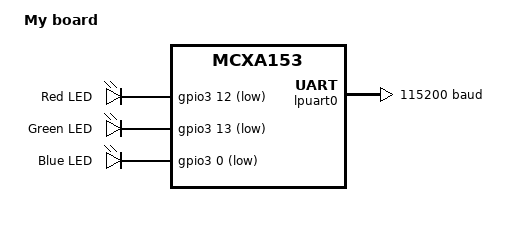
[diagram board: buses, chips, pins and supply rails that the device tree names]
/dts-v1/;

#include <nxp/nxp_mcxa153.dtsi>
#include "hello_world_scratch_method.dtsi"


/ {
	model = "My board";
	compatible = "iomico,my_board";

	aliases{
		led0 = &red_led;
		led1 = &green_led;
		led2 = &blue_led;
	};

	chosen{
		zephyr,sram = &sram0;
		zephyr,flash = &flash;
		zephyr,flash-controller = &fmu;
		zephyr,code-partition = &slot0_partition;
		zephyr,console = &lpuart0;
		zephyr,shell-uart = &lpuart0;
	};

	leds{
		compatible = "gpio-leds";

		red_led: led_0 {
			gpios = <&gpio3 12 GPIO_ACTIVE_LOW>;
			label = "Red LED";
		};

		green_led: led_1 {
			gpios = <&gpio3 13 GPIO_ACTIVE_LOW>;
			label = "Green LED";
		};

		blue_led: led_2 {
			gpios = <&gpio3 0 GPIO_ACTIVE_LOW>;
			label = "Blue LED";
		};
	};
};

&gpio3 {
	status = "okay";
};

&flash {
	partitions {
		compatible = "fixed-partitions";
		#address-cells = <1>;
		#size-cells = <1>;

		boot_partition: partition@0 {
			label = "mcuboot";
			reg = <0x00000000 DT_SIZE_K(32)>;
			read-only;
		};
		slot0_partition: partition@8000 {
			label = "image-0";
			reg = <0x00008000 DT_SIZE_K(40)>;
		};
		slot1_partition: partition@12000 {
			label = "image-1";
			reg = <0x00012000 DT_SIZE_K(40)>;
		};
		storage_partition: partition@1C000 {
			label = "storage";
			reg = <0x0001C000 DT_SIZE_K(16)>;
		};
	};
};

&lpuart0 {
	status = "okay";
	current-speed = <115200>;
	pinctrl-0 = <&pinmux_lpuart0>;
	pinctrl-names = "default";
};

